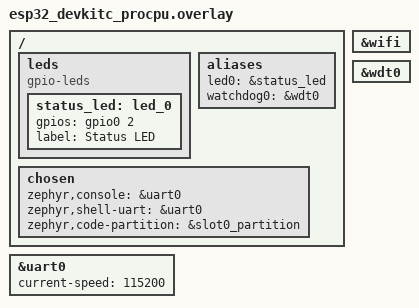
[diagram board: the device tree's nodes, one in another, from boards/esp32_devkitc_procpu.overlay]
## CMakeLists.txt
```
# SPDX-License-Identifier: Apache-2.0

cmake_minimum_required(VERSION 3.20.0)

find_package(Zephyr REQUIRED HINTS $ENV{ZEPHYR_BASE})
project(sample_with_mcuboot)

# Verify that this sample is built through sysbuild to ensure MCUboot is
# automatically included and that sample specific MCUboot configurations are
# used when building MCUboot.
test_sysbuild()

# Fügt Ihre C-Quelldateien zum "app"-Ziel hinzu.
target_sources(app PRIVATE
    src/main.c
    src/blinky.c
    src/wifi_mgmt.c
    src/ota_mgmt.c
    src/watchdog_mgmt.c
)

#set(DTC_OVERLAY_FILE ${CMAKE_CURRENT_SOURCE_DIR}/boards/${BOARD}.overlay)

target_include_directories(app PRIVATE 
    include
)
```

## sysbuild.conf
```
SB_CONFIG_BOOTLOADER_MCUBOOT=y
SB_CONFIG_BOOT_SIGNATURE_TYPE_ECDSA_P256=y
#SB_CONFIG_BOOT_SIGNATURE_TYPE_ED25519=y
SB_CONFIG_BOOT_SIGNATURE_KEY_FILE="C:/Users/SebastianR/Desktop/repos/zephyr-blinky-ota/zephyr-project/ecdsa.pem"

# necessary for some reason, as the mcuboot.conf is being overwritten or so
#SB_CONFIG_MCUBOOT_MODE_SWAP_SCRATCH=y
SB_CONFIG_MCUBOOT_MODE_SWAP_USING_MOVE=y
```

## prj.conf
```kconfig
# Empty file
# ======== Logging ========
CONFIG_LOG=y
#CONFIG_LOG_DEFAULT_LEVEL=3

# ======== Shell ========
CONFIG_SHELL=y
CONFIG_SHELL_BACKEND_SERIAL=y

# ======== Basic System and Hardware ========
CONFIG_GPIO=y
CONFIG_WATCHDOG=y
CONFIG_REBOOT=y
CONFIG_MAIN_STACK_SIZE=4096
CONFIG_SYSTEM_WORKQUEUE_STACK_SIZE=2048
CONFIG_HEAP_MEM_POOL_SIZE=65536

# ======== Networking =======
CONFIG_NETWORKING=y
CONFIG_NET_IPV4=y
CONFIG_NET_DHCPV4=y
CONFIG_NET_TCP=y
CONFIG_NET_SOCKETS=y
CONFIG_NET_MGMT=y
CONFIG_NET_MGMT_EVENT=y
CONFIG_NET_BUF_RX_COUNT=16
CONFIG_NET_BUF_TX_COUNT=16

# ======== WiFi ========
CONFIG_WIFI=y
CONFIG_WIFI_ESP32=y
CONFIG_NET_L2_WIFI_MGMT=y
CONFIG_HTTP_CLIENT=y

# ======== JSON Library ========
CONFIG_JSON_LIBRARY=y
# ======== MCUboot & OTA Support for the Application ========

CONFIG_IMG_MANAGER=y
CONFIG_MCUBOOT_IMG_MANAGER=y
CONFIG_IMG_BLOCK_BUF_SIZE=512
#CONFIG_MCUBOOT_SHELL=y # Erlaubt OTA-Befehle über die serielle Konsole
CONFIG_MCUBOOT_IMGTOOL_SIGN_VERSION="1.0.2+2"

#CONFIG_BOOT_IMAGE_ACCESS_HOOKS=y
# ======== Flash Configuration ========
CONFIG_FLASH=y
CONFIG_FLASH_MAP=y
CONFIG_STREAM_FLASH=y
CONFIG_FLASH_PAGE_LAYOUT=y

# ======== ESP32 Specific Flash Settings ========
CONFIG_ESPTOOLPY_FLASHMODE_QIO=y
CONFIG_ESPTOOLPY_FLASHFREQ_80M=y
CONFIG_ESPTOOLPY_FLASHSIZE_4MB=y

CONFIG_BOOTLOADER_MCUBOOT=y
CONFIG_IMG_BLOCK_BUF_SIZE=1024

CONFIG_GPIO_ESP32=y
CONFIG_PINCTRL=y

# For debugging GPIO issues
CONFIG_GPIO_SHELL=y
CONFIG_DEVICE_SHELL=y
```

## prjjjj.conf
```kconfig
# Empty file
# ======== Logging ========
CONFIG_LOG=y
#CONFIG_LOG_DEFAULT_LEVEL=3

# ======== Shell ========
CONFIG_SHELL=y
CONFIG_SHELL_BACKEND_SERIAL=y

# ======== Basic System and Hardware ========
CONFIG_GPIO=y
CONFIG_WATCHDOG=y
CONFIG_REBOOT=y
CONFIG_MAIN_STACK_SIZE=4096
CONFIG_SYSTEM_WORKQUEUE_STACK_SIZE=2048
CONFIG_HEAP_MEM_POOL_SIZE=65536

# ======== Networking =======
CONFIG_NETWORKING=y
CONFIG_NET_IPV4=y
CONFIG_NET_DHCPV4=y
CONFIG_NET_TCP=y
CONFIG_NET_SOCKETS=y
CONFIG_NET_MGMT=y
CONFIG_NET_MGMT_EVENT=y
CONFIG_NET_BUF_RX_COUNT=16
CONFIG_NET_BUF_TX_COUNT=16

# ======== WiFi ========
CONFIG_WIFI=y
CONFIG_WIFI_ESP32=y
CONFIG_NET_L2_WIFI_MGMT=y
CONFIG_HTTP_CLIENT=y

# ======== JSON Library ========
CONFIG_JSON_LIBRARY=y
# ======== MCUboot & OTA Support for the Application ========
#CONFIG_IMG_MANAGER=y
#CONFIG_MCUBOOT_IMG_MANAGER=y
#CONFIG_MCUBOOT_SHELL=y # Erlaubt OTA-Befehle über die serielle Konsole
CONFIG_MCUBOOT_IMGTOOL_SIGN_VERSION="1.0.2+2"

#CONFIG_BOOT_IMAGE_ACCESS_HOOKS=y
# ======== Flash Configuration ========
CONFIG_FLASH=y
CONFIG_FLASH_MAP=y
CONFIG_STREAM_FLASH=y
CONFIG_FLASH_PAGE_LAYOUT=y

# ======== ESP32 Specific Flash Settings ========
CONFIG_ESPTOOLPY_FLASHMODE_QIO=y
CONFIG_ESPTOOLPY_FLASHFREQ_80M=y
CONFIG_ESPTOOLPY_FLASHSIZE_4MB=y

CONFIG_BOOTLOADER_MCUBOOT=y
CONFIG_IMG_BLOCK_BUF_SIZE=1024

CONFIG_GPIO_ESP32=y
CONFIG_PINCTRL=y

# For debugging GPIO issues
CONFIG_GPIO_SHELL=y
CONFIG_DEVICE_SHELL=y
```

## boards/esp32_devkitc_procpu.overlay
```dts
/*
 * Application-specific hardware configuration and flash layout.
 * The flash partition map here MUST match the one in the .yml file.
 */

/ {
    /* Board-specific hardware customization for your application */
    leds {
        compatible = "gpio-leds";
        status_led: led_0 {
            gpios = <&gpio0 2 GPIO_ACTIVE_HIGH>;
            label = "Status LED";
        };
    };

    aliases {
        led0 = &status_led;
        watchdog0 = &wdt0;
    };

    chosen {
        zephyr,console = &uart0;
        zephyr,shell-uart = &uart0;
        zephyr,code-partition = &slot0_partition; /* Tells Zephyr where the app runs */
    };
};

&uart0 {
    status = "okay";
    current-speed = <115200>;
};

&wifi {
    status = "okay";
};

&wdt0 {
    status = "okay";
};
```

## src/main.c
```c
#include <zephyr/kernel.h>
#include <zephyr/logging/log.h>
#include <zephyr/dfu/mcuboot.h>

#include "app_config.h"
#include "blinky.h"
#include "wifi_mgmt.h"
#include "ota_mgmt.h"
#include "watchdog_mgmt.h"

LOG_MODULE_REGISTER(main, LOG_LEVEL_INF);

// Define a work item for the delayed confirmation
static void confirm_work_handler(struct k_work *work);
static K_WORK_DELAYABLE_DEFINE(confirm_work, confirm_work_handler);
static int main_task_handle;

static void confirm_work_handler(struct k_work *work)
{
    LOG_INF("Confirming running firmware as valid.");
    if (boot_write_img_confirmed() != 0) {
        LOG_ERR("Failed to confirm image! This may cause a revert on next boot.");
    } else {
        LOG_INF("Image confirmed successfully. The update is now permanent.");
        ota_check_for_update();
    }
}

/* OTA status callback */
static void ota_status_changed(ota_status_t status)
{
    switch (status) {
    case OTA_STATUS_CHECKING:
        LOG_INF("OTA: Checking for updates...");
        break;
    case OTA_STATUS_UPDATE_AVAILABLE:
        LOG_INF("OTA: Update available, preparing download");
        break;
    case OTA_STATUS_DOWNLOADING:
        LOG_INF("OTA: Downloading firmware update");
        break;
    case OTA_STATUS_DOWNLOAD_COMPLETE:
        LOG_INF("OTA: Download complete, preparing to apply");
        break;
    case OTA_STATUS_APPLYING:
        LOG_INF("OTA: Applying update, device will reboot");
        break;
    case OTA_STATUS_ERROR:
        LOG_ERR("OTA: Error occurred, code: %d", ota_get_last_error());
        break;
    default:
        break;
    }
}

int main(void)
{    
    LOG_INF("====================================");
    LOG_INF("   ESP32 OTA Application Booting    ");
    LOG_INF("====================================");

    // This is the most important part after an OTA update.
    // Check if we are running an unconfirmed image.
    if (boot_is_img_confirmed() == 0) {
        LOG_WRN("Running new firmware in TEST mode.");
        LOG_WRN("Scheduling confirmation in 30 seconds.");
        // We wait 30 seconds to ensure the system is stable (e.g., WiFi connects)
        // before making the update permanent.
        k_work_schedule(&confirm_work, K_SECONDS(30));
    } else {
        LOG_INF("Running a confirmed image.");
    }

    ota_register_status_callback(ota_status_changed);
    char current_ver[16];
    int rc = ota_get_running_firmware_version(current_ver, sizeof(current_ver));
    if (rc == 0) {
        LOG_INF("Current running version: %s", current_ver);
    } else {
        LOG_WRN("Somethings wrong with the version getter");
    }
    bool ip_printed = false;

    watchdog_manager_init(K_SECONDS(30));
    LOG_INF("Watchdog initialized!");
    main_task_handle = watchdog_manager_register_task();

    LOG_INF("Main loop started. System is running.");
    while (1) {
        k_sleep(K_SECONDS(5));
        watchdog_manager_check_in(main_task_handle);

        if(!ip_printed) {
            char ip_str[16];
            int result = wifi_get_ip_address_public(ip_str, sizeof(ip_str));
            if (result == 0) {
                LOG_INF("IP: %s", ip_str);
                ip_printed = true;
            } else {
                LOG_INF("No IP");
            }
        }
    }
    
    return 0;
}
```

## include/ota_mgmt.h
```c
#ifndef OTA_MGMT_H
#define OTA_MGMT_H

#include <zephyr/kernel.h>
#include <stdint.h>
#include <stdbool.h>
#include <zephyr/dfu/mcuboot.h>

#ifdef __cplusplus
extern "C" {
#endif

/* OTA update status codes */
typedef enum {
    OTA_STATUS_IDLE = 0,
    OTA_STATUS_CHECKING,
    OTA_STATUS_UPDATE_AVAILABLE,
    OTA_STATUS_DOWNLOADING,
    OTA_STATUS_DOWNLOAD_COMPLETE,
    OTA_STATUS_APPLYING,
    OTA_STATUS_ERROR,
} ota_status_t;

/* OTA error codes */
typedef enum {
    OTA_ERR_NONE = 0,
    OTA_ERR_SERVER_CONNECT,
    OTA_ERR_DOWNLOAD_FAILED,
    OTA_ERR_FLASH_INIT,
    OTA_ERR_FLASH_WRITE,
    OTA_ERR_VERIFICATION,
    OTA_ERR_APPLY_UPDATE,
    OTA_ERR_INVALID_IMAGE,
} ota_error_t;

/**
 * @brief Initialize OTA management subsystem
 * 
 * This function is called automatically during system initialization.
 * 
 * @return 0 on success, negative error code on failure
 */
int ota_mgmt_init(void);

/**
 * @brief Manually trigger an OTA update check
 * 
 * @return 0 if check was started, negative error code on failure
 */
int ota_check_for_update(void);

/**
 * @brief Get current OTA status
 * 
 * @return Current OTA status code
 */
ota_status_t ota_get_status(void);

/**
 * @brief Get last OTA error
 * 
 * @return Last error code
 */
ota_error_t ota_get_last_error(void);

/**
 * @brief Register callback for OTA status changes
 * 
 * @param callback Function to call when OTA status changes
 */
void ota_register_status_callback(void (*callback)(ota_status_t status));

/**
 * @brief Get the version of the currently running firmware.
 *
 * This function reads the image header from the primary (active) slot,
 * formats the semantic version into a string, and stores it in the
 * provided buffer.
 *
 * @param buf       A character buffer to store the version string.
 * @param buf_size  The size of the provided buffer.
 *
 * @return 0 on success.
 * @return -EIO if the image header could not be read.
 * @return -ENOMEM if the provided buffer is too small to hold the version string.
 * @return A negative error code from the underlying boot/flash functions on other failures.
 */
int ota_get_running_firmware_version(char *buf, size_t buf_size);

static void ota_enter_backoff_state(void);

#ifdef __cplusplus
}
#endif

#endif /* OTA_MGMT_H */
```

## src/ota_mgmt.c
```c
#include <zephyr/kernel.h>
#include <zephyr/net/socket.h>
#include <zephyr/storage/flash_map.h>
#include <zephyr/dfu/mcuboot.h>
#include <zephyr/storage/stream_flash.h>
#include <zephyr/sys/reboot.h>
#include <zephyr/logging/log.h>
#include <zephyr/init.h>
#include <zephyr/net/http/client.h>
#include <zephyr/net/net_ip.h>
#include <zephyr/data/json.h>
#include <string.h>
#include "wifi_mgmt.h"
#include "app_config.h"
#include "ota_mgmt.h"
#include "blinky.h"
#include <zephyr/devicetree.h>
#include <zephyr/dfu/flash_img.h>
#include <stdio.h>
#include "watchdog_mgmt.h"


LOG_MODULE_REGISTER(ota_mgmt, LOG_LEVEL_INF);

struct flash_img_context image_ctx;

/* OTA state variables */
static struct k_work_delayable ota_check_work;
static ota_status_t current_status = OTA_STATUS_IDLE;
static ota_error_t last_error = OTA_ERR_NONE;
static void (*status_callback)(ota_status_t) = NULL;

/* HTTP client context */
static struct http_request http_req;
static uint8_t http_recv_buf[1024];
static int64_t content_length = 0;
static size_t total_downloaded = 0;
static bool headers_complete = false;
static int retry_count = 0;
static int http_sock = -1;

/* Watchdog */
static int ota_task_handle = -1;

/* Version parsing from JSON */
struct version_info {
    const char *version;
    int size;
};

static struct json_obj_descr version_descr[] = {
    JSON_OBJ_DESCR_PRIM(struct version_info, version, JSON_TOK_STRING),
    JSON_OBJ_DESCR_PRIM(struct version_info, size, JSON_TOK_NUMBER),
};

/* Forward declarations */
static void ota_check_work_handler(struct k_work *work);
static int perform_update(void);
static void update_status(ota_status_t new_status);
static int apply_update(void);
static int create_http_socket(const char *host, int port);
static void ota_enter_backoff_state(void);


/* Update OTA status and trigger callback if registered */
static void update_status(ota_status_t new_status)
{
    if (current_status != new_status) {
        current_status = new_status;
        
        /* Update LED pattern based on status */
        switch (new_status) {
        case OTA_STATUS_DOWNLOADING:
            blinky_set_interval(LED_SLOW_BLINK_MS);
            break;
        case OTA_STATUS_APPLYING:
            blinky_set_interval(LED_FAST_BLINK_MS);
            break;
        case OTA_STATUS_ERROR:
            blinky_set_interval(LED_ERROR_PATTERN);
            break;
        default:
            blinky_set_interval(LED_BLINK_INTERVAL_MS);
            break;
        }
        
        if (status_callback != NULL) {
            status_callback(new_status);
        }
    }
}

/* Set error and update status */
static void set_error(ota_error_t error)
{
    last_error = error;
    update_status(OTA_STATUS_ERROR);
}

/* Direkte Boot-Trailer Manipulation */
static int manual_boot_request_upgrade(void)
{
    const struct flash_area *fa;
    int ret;
    
    ret = flash_area_open(DT_FIXED_PARTITION_ID(DT_NODELABEL(slot1_partition)), &fa);
    if (ret) {
        LOG_ERR("Cannot open slot1: %d", ret);
        return ret;
    }
    
    /* Boot-Trailer am Ende von Slot1 schreiben */
    struct {
        uint8_t image_ok;
        uint8_t copy_done;
        uint8_t reserved[14];
        uint32_t magic;
    } __packed trailer = {
        .image_ok = 0x01,     // BOOT_FLAG_SET
        .copy_done = 0xFF,    // BOOT_FLAG_UNSET
        .magic = 0x96f3b83c   // BOOT_MAGIC
    };
    
    size_t trailer_offset = fa->fa_size - sizeof(trailer);
    
    ret = flash_area_write(fa, trailer_offset, &trailer, sizeof(trailer));
    if (ret) {
        LOG_ERR("Failed to write boot trailer: %d", ret);
        flash_area_close(fa);
        return ret;
    }
    
    LOG_INF("✓ Boot trailer written manually");
    flash_area_close(fa);
    return 0;
}

void debug_image_headers(void)
{
    LOG_INF("=== Image Header Debug ===");
    
    struct mcuboot_img_header header;
    int ret;
    
    /* Slot0 (aktuell laufend) prüfen */
    ret = boot_read_bank_header(DT_FIXED_PARTITION_ID(DT_NODELABEL(slot0_partition)), &header, sizeof(header));
    if (ret == 0) {
        LOG_INF("Slot0 - Image size: %u", header.h.v1.image_size);
        LOG_INF("Slot0 - Version: %u.%u.%u+%u", 
               header.h.v1.sem_ver.major,
               header.h.v1.sem_ver.minor,
               header.h.v1.sem_ver.revision,
               header.h.v1.sem_ver.build_num);
    } else {
        LOG_ERR("Failed to read slot0 header: %d", ret);
    }
    
    /* Slot1 (OTA Update) prüfen */
    ret = boot_read_bank_header(DT_FIXED_PARTITION_ID(DT_NODELABEL(slot1_partition)), &header, sizeof(header));
    if (ret == 0) {
        LOG_INF("✓ Slot1 - Valid image found!");
        LOG_INF("Slot1 - Image size: %u", header.h.v1.image_size);
        LOG_INF("Slot1 - Version: %u.%u.%u+%u", 
               header.h.v1.sem_ver.major,
               header.h.v1.sem_ver.minor,
               header.h.v1.sem_ver.revision,
               header.h.v1.sem_ver.build_num);
    } else {
        LOG_ERR("✗ Slot1 - No valid image found: %d", ret);
        
        /* Raw Flash-Daten zur Diagnose lesen */
        const struct flash_area *fa;
        if (flash_area_open(DT_FIXED_PARTITION_ID(DT_NODELABEL(slot1_partition)), &fa) == 0) {
            uint32_t magic;
            flash_area_read(fa, 0, &magic, sizeof(magic));
            LOG_ERR("Slot1 raw magic: 0x%08x (expected: 0x96f3b83d)", magic);
            flash_area_close(fa);
        }
    }
}

int ota_get_running_firmware_version(char *buf, size_t buf_size)
{
    struct mcuboot_img_header header;
    int rc;

    /*
     * Use boot_fetch_active_slot() to reliably get the ID of the slot
     * from which the current application was booted. This is more robust
     * than hardcoding the slot0 ID, especially in revert scenarios.
     */
    uint8_t active_slot_id = boot_fetch_active_slot();

    rc = boot_read_bank_header(active_slot_id, &header, sizeof(header));
    if (rc != 0) {
        LOG_ERR("Failed to read running image header from slot %u. Error: %d",
                active_slot_id, rc);
        return rc; // Propagate the error (-EIO is common for empty/bad slots)
    }

    /* Format the version string into the provided buffer */
    rc = snprintf(buf, buf_size, "%u.%u.%u",
                  header.h.v1.sem_ver.major,
                  header.h.v1.sem_ver.minor,
                  header.h.v1.sem_ver.revision);

    /*
     * snprintf returns the number of characters that *would have been* written.
     * We must check if this number is greater than or equal to the buffer size,
     * which indicates truncation.
     */
    if (rc < 0 || rc >= buf_size) {
        LOG_ERR("Buffer too small for version string. Required: %d, available: %zu",
                rc, buf_size);
        return -ENOMEM; // No memory/space available
    }

    return 0; // Success
}

/* Create HTTP socket connection */
static int create_http_socket(const char *host, int port)
{
    struct zsock_addrinfo hints, *result;
    //struct sockaddr_in addr;
    int sock;
    int ret;
    
    sock = zsock_socket(AF_INET, SOCK_STREAM, IPPROTO_TCP);
    if (sock < 0) {
        LOG_ERR("Failed to create socket: %d", errno);
        return -1;
    }
    
    /* Set socket timeout */
    struct zsock_timeval timeout = {
        .tv_sec = 30,
        .tv_usec = 0,
    };
    
    zsock_setsockopt(sock, SOL_SOCKET, SO_RCVTIMEO, &timeout, sizeof(timeout));
    zsock_setsockopt(sock, SOL_SOCKET, SO_SNDTIMEO, &timeout, sizeof(timeout));
    
    /* Setup address resolution */
    memset(&hints, 0, sizeof(hints));
    hints.ai_family = AF_INET;
    hints.ai_socktype = SOCK_STREAM;
    
    char port_str[8];
    snprintf(port_str, sizeof(port_str), "%d", port);
    
    ret = zsock_getaddrinfo(host, port_str, &hints, &result);
    if (ret != 0) {
        LOG_ERR("Failed to resolve hostname %s: %d", host, ret);
        zsock_close(sock);
        return -1;
    }
    
    /* Connect */
    ret = zsock_connect(sock, result->ai_addr, result->ai_addrlen);
    zsock_freeaddrinfo(result);
    
    if (ret < 0) {
        LOG_ERR("Failed to connect to %s:%d: %d", host, port, errno);
        zsock_close(sock);
        return -1;
    }
    
    LOG_INF("Connected to %s:%d", host, port);
    return sock;
}

/* HTTP response callback */
static int http_response_cb(struct http_response *rsp, enum http_final_call final_data, void *user_data)
{
    int ret = 0;
    
    /* Feed watchdog to prevent reset during download */
    watchdog_manager_check_in(ota_task_handle);

    /* Check if this is the first time we get body data */
    if (!headers_complete && rsp->body_frag_len > 0) {
        if (rsp->http_status_code != 200) {
            LOG_ERR("HTTP request failed with status: %d %s", rsp->http_status_code, rsp->http_status);
            set_error(OTA_ERR_DOWNLOAD_FAILED);
            return -1;
        }
        headers_complete = true;
        content_length = rsp->content_length;
        LOG_INF("HTTP headers complete, content length: %lld", content_length);
        
        /* If checking version, parse the JSON response */
        if (current_status == OTA_STATUS_CHECKING) {
            struct version_info version = {0};
            
            ret = json_obj_parse(rsp->body_frag_start, rsp->body_frag_len,
                               version_descr, ARRAY_SIZE(version_descr),
                               &version);
            
            if (ret > 0 && version.version) {
                LOG_INF("Server version: %s", version.version);
                
                /* Compare with current version */
                char current_ver[16];
                int rc = ota_get_running_firmware_version(current_ver, sizeof(current_ver));
                if (strcmp(version.version, current_ver) != 0) {
                    LOG_INF("New version available: %s (current: %s)",
                           version.version, current_ver);
                    update_status(OTA_STATUS_UPDATE_AVAILABLE);
                    
                    /* Start download after a short delay */
                    k_work_schedule(&ota_check_work, K_SECONDS(5));
                } else {
                    LOG_INF("Already running latest version");
                    update_status(OTA_STATUS_IDLE);
                }
            } else {
                LOG_ERR("Failed to parse version info");
                set_error(OTA_ERR_SERVER_CONNECT);
            }
            
            return 0;
        }

        if (current_status == OTA_STATUS_DOWNLOADING) {
            LOG_INF("Flash initialized for firmware download");
            total_downloaded = 0;
        }
    }
    
    /* Process body data for firmware download */
    if (headers_complete && current_status == OTA_STATUS_DOWNLOADING && 
        rsp->body_frag_len > 0) {
        
        ret = flash_img_buffered_write(&image_ctx, 
                rsp->body_frag_start,
                rsp->body_frag_len, 
                (final_data == HTTP_DATA_FINAL));

        if (ret < 0) {
            LOG_ERR("Flash write error: %d", ret);
            set_error(OTA_ERR_FLASH_WRITE);
            return ret;
        }
        
        total_downloaded += rsp->body_frag_len;
        
        if (total_downloaded % 4096 == 0 || final_data == HTTP_DATA_FINAL) {
            double progress = (double)total_downloaded * 100.0 / content_length;
            LOG_INF("Downloaded: %zu bytes (%.1f%%)", total_downloaded, progress);
        }
        
        /* Check if download is complete */
        if (final_data == HTTP_DATA_FINAL) {
            LOG_INF("Firmware download complete: %zu bytes", total_downloaded);
        }
    }
    
    return 0;
}

/* Check for firmware updates */
static int check_for_update(void)
{
    if (!wifi_is_connected()) {
        LOG_WRN("WiFi not connected (yet), skipping update check");
        return -ENOTCONN;
    }
    
    update_status(OTA_STATUS_CHECKING);
    
    /* try to create socket connection */
    http_sock = create_http_socket(OTA_SERVER_HOST, OTA_SERVER_PORT);
    if (http_sock < 0) {
        LOG_ERR("Server connection failed. Entering 1-hour backoff.");
        ota_enter_backoff_state();
        return http_sock;
    }
    
    /* Setup HTTP request for version check */
    memset(&http_req, 0, sizeof(http_req));
    
    http_req.method = HTTP_GET;
    http_req.url = OTA_VERSION_URL;
    http_req.host = OTA_SERVER_HOST;
    http_req.protocol = "HTTP/1.1";
    http_req.response = http_response_cb;
    http_req.recv_buf = http_recv_buf;
    http_req.recv_buf_len = sizeof(http_recv_buf);
    
    headers_complete = false;
    
    LOG_INF("Checking for updates at http://%s:%d%s", OTA_SERVER_HOST, OTA_SERVER_PORT, OTA_VERSION_URL);
    int ret = http_client_req(http_sock, &http_req, 5000, NULL); //blocks until done
    
    /* Close socket */
    zsock_close(http_sock);
    http_sock = -1;
    
    /* in case something went wrong */
    if (ret < 0) {
        LOG_ERR("Server connection failed. Entering 1-hour backoff.");
        ota_enter_backoff_state();
    }
    
    return ret;
}

/* Download and install firmware update */
static int perform_update(void)
{
    LOG_INF("Tryning to download firmware");

    if (!wifi_is_connected()) {
        LOG_WRN("WiFi not connected, cannot download update");
        ota_enter_backoff_state();
        return -ENOTCONN;
    }
    
    update_status(OTA_STATUS_DOWNLOADING);
    
    //int ret = flash_img_init(&image_ctx);
    int ret = flash_img_init_id(&image_ctx, DT_FIXED_PARTITION_ID(DT_NODELABEL(slot1_partition)));
    LOG_INF("area ID of slot1: %d", DT_FIXED_PARTITION_ID(DT_NODELABEL(slot1_partition)));

    if (ret != 0) {
        LOG_ERR("Failed to initialize flash context: %d", ret);
        set_error(OTA_ERR_FLASH_INIT);
        ota_enter_backoff_state();
        return ret;
    }

    uint8_t area_id = flash_img_get_upload_slot();
    LOG_INF("Flash image using area ID: %d", area_id);

    /* Create socket connection */
    http_sock = create_http_socket(OTA_SERVER_HOST, OTA_SERVER_PORT);
    if (http_sock < 0) {
        set_error(OTA_ERR_SERVER_CONNECT);
        LOG_ERR("Server connection failed. Entering 1-hour backoff.");
        ota_enter_backoff_state();
        return -ECONNREFUSED;
    }
    /* Setup HTTP request for firmware download */
    memset(&http_req, 0, sizeof(http_req));

    http_req.method = HTTP_GET;
    http_req.url = OTA_FIRMWARE_URL;
    http_req.host = OTA_SERVER_HOST;
    http_req.protocol = "HTTP/1.1";
    http_req.response = http_response_cb;
    http_req.recv_buf = http_recv_buf;
    http_req.recv_buf_len = sizeof(http_recv_buf);
    
    headers_complete = false;
    total_downloaded = 0; 

    LOG_INF("Downloading firmware from http://%s:%d%s", OTA_SERVER_HOST, OTA_SERVER_PORT, OTA_FIRMWARE_URL);

    ret = http_client_req(http_sock, &http_req, OTA_DOWNLOAD_TIMEOUT_MS, NULL); // blocks until done

    /* Close socket */
    zsock_close(http_sock);
    http_sock = -1;
    
    if (ret < 0) {
        LOG_ERR("Failed to download firmware: %d", ret);
        set_error(OTA_ERR_DOWNLOAD_FAILED);
        
        /* Retry logic */
        if (++retry_count < OTA_MAX_DOWNLOAD_RETRIES) {
            LOG_INF("Retrying download (%d/%d) in 5 seconds...", 
                   retry_count + 1, OTA_MAX_DOWNLOAD_RETRIES);
            k_work_schedule(&ota_check_work, K_SECONDS(5));
        } else {
            LOG_ERR("Max retry attempts reached, giving up");
            retry_count = 0;
            update_status(OTA_STATUS_IDLE);
            ota_enter_backoff_state();
        }
    } else {
        LOG_INF("Firmware download successful.");
        update_status(OTA_STATUS_DOWNLOAD_COMPLETE);

        // The download is fully complete, and the HTTP client is closed.
        // The image_ctx is no longer in active use. NOW it is safe
        // to schedule the final "apply" step.
        k_work_schedule(&ota_check_work, K_MSEC(100)); // A short delay is fine.
        /* Reset retry counter on success */
        retry_count = 0;
    }
    
    return ret;
}

/* Apply downloaded update */
static int apply_update(void)
{
    update_status(OTA_STATUS_APPLYING);
    
    LOG_INF("=== Boot Status Debug ===");
    int swap_type = mcuboot_swap_type();
    LOG_INF("Current swap type: %d", swap_type);

    const struct flash_area *fa;
    uint32_t magic;
    int ret_dbg;
    
    
    /* Slot1 direkt aus Flash lesen */
    ret_dbg = flash_area_open(DT_FIXED_PARTITION_ID(DT_NODELABEL(slot1_partition)), &fa);
    if (ret_dbg != 0) {
        LOG_ERR("Cannot open slot1: %d", ret_dbg);
        return ret_dbg;
    }
    
    /* Erste 4 Bytes lesen (das ist der Magic-Wert) */
    ret_dbg = flash_area_read(fa, 0, &magic, sizeof(magic));
    if (ret_dbg == 0) {
        LOG_INF("Slot1 - First 4 bytes (magic): 0x%08x", magic);
    }

    debug_image_headers();

    /* Mark image for testing */
    int ret = boot_request_upgrade(BOOT_UPGRADE_TEST);
    //int ret = manual_boot_request_upgrade();
    if (ret != 0) {
        LOG_ERR("Failed to request upgrade: %d", ret);
        set_error(OTA_ERR_APPLY_UPDATE);
        return ret;
    }
    
    LOG_INF("Update ready - rebooting in 3 seconds");
    watchdog_manager_check_in(ota_task_handle);
    k_sleep(K_SECONDS(3));
    sys_reboot(SYS_REBOOT_WARM); //SYS_REBOOT_COLD
    
    return 0; /* Will never reach here */
}

/* OTA check work handler */
static void ota_check_work_handler(struct k_work *work)
{
    ARG_UNUSED(work);
    
    if (!watchdog_manager_is_monitoring_enabled(ota_task_handle)) {
        LOG_INF("OTA is in backoff state. Will try again later.");
        watchdog_manager_enable_monitoring(ota_task_handle, true);
        update_status(OTA_STATUS_IDLE);
        return;
    }

    watchdog_manager_check_in(ota_task_handle);
    
    switch (current_status) {
        case OTA_STATUS_IDLE:
            check_for_update();
            break;
            
        case OTA_STATUS_UPDATE_AVAILABLE:
            perform_update();
            break;
            
        case OTA_STATUS_DOWNLOAD_COMPLETE:
            apply_update();
            break;
            
        default:
            break;
    }
}

static void ota_enter_backoff_state(void) {
    watchdog_manager_enable_monitoring(ota_task_handle, false);
    k_work_schedule(&ota_check_work, K_HOURS(1));
    set_error(OTA_ERR_SERVER_CONNECT);
}

/* Public functions */
int ota_check_for_update(void)
{
    if (current_status != OTA_STATUS_IDLE) {
        LOG_WRN("OTA operation already in progress");
        return -EBUSY;
    }
    
    return check_for_update();
}

ota_status_t ota_get_status(void)
{
    return current_status;
}

ota_error_t ota_get_last_error(void)
{
    return last_error;
}

void ota_register_status_callback(void (*callback)(ota_status_t status))
{
    status_callback = callback;
}

int ota_mgmt_init(void)
{
    ota_task_handle = watchdog_manager_register_task();

    k_work_init_delayable(&ota_check_work, ota_check_work_handler);

    if (boot_is_img_confirmed()) {
        LOG_INF("Scheduling initial OTA check in 30 seconds.");
        k_work_schedule(&ota_check_work, K_SECONDS(30));
    }

    LOG_INF("OTA management subsystem initialized");
    return 0;
}

/* Auto-initialize at APPLICATION level */
SYS_INIT(ota_mgmt_init, APPLICATION, CONFIG_APPLICATION_INIT_PRIORITY);
```

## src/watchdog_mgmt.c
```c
#include "watchdog_mgmt.h"
#include <zephyr/drivers/watchdog.h>
#include <zephyr/logging/log.h>
#include <stdatomic.h>

LOG_MODULE_REGISTER(wdt_mgr, LOG_LEVEL_INF);

#define MAX_MONITORED_TASKS 4 // Maximale Anzahl an Tasks, die überwacht werden können

static const struct device *wdt_dev;
static int wdt_channel_id;

static atomic_uint g_task_check_ins[MAX_MONITORED_TASKS];
static atomic_bool g_task_monitoring_enabled[MAX_MONITORED_TASKS];
static atomic_int g_registered_tasks_count = ATOMIC_VAR_INIT(0);

static struct k_timer wdt_mgr_timer;

/*
 * This is the core logic. It's a timer callback that runs periodically.
 */
static void watchdog_manager_check_tasks(struct k_timer *timer)
{
    bool all_active_tasks_ok = true;
    int task_count = atomic_load(&g_registered_tasks_count);

    for (int i = 0; i < task_count; i++) {
        // ONLY check tasks that are supposed to be active.
        if (atomic_load(&g_task_monitoring_enabled[i])) {
            if (atomic_exchange(&g_task_check_ins[i], 0) == 0) {
                LOG_ERR("Watchdog: Monitored task %d failed to check in!", i);
                all_active_tasks_ok = false;
            }
        }
    }

    if (all_active_tasks_ok) {
        if (wdt_dev) {
            wdt_feed(wdt_dev, wdt_channel_id);
            LOG_DBG("All %d tasks checked in. Watchdog fed.", task_count);
        }
    } else {
        LOG_WRN("Watchdog not fed due to missing check-in. System will reset soon.");
        // We do nothing, letting the hardware watchdog time out.
    }
}

int watchdog_manager_init(k_timeout_t check_interval)
{
    wdt_dev = DEVICE_DT_GET(DT_ALIAS(watchdog0));
    if (!device_is_ready(wdt_dev)) {
        LOG_ERR("Hardware watchdog device not found or not ready.");
        return -ENODEV;
    }

    struct wdt_timeout_cfg wdt_config = {
        .window.min = 0,
        .window.max = 60000, // 60-Sekunden-Hardware-Timeout
        .callback = NULL,
        .flags = WDT_FLAG_RESET_SOC,
    };
    wdt_channel_id = wdt_install_timeout(wdt_dev, &wdt_config);
    if (wdt_channel_id < 0) {
        LOG_ERR("Failed to install watchdog timeout: %d", wdt_channel_id);
        return wdt_channel_id;
    }
    wdt_setup(wdt_dev, WDT_OPT_PAUSE_HALTED_BY_DBG);

    // Initialisiere und starte unseren periodischen Software-Check-Timer
    k_timer_init(&wdt_mgr_timer, watchdog_manager_check_tasks, NULL);
    k_timer_start(&wdt_mgr_timer, check_interval, check_interval);

    LOG_INF("Watchdog Manager initialized. Check interval: %llu ms, HW timeout: %u ms",
            check_interval.ticks, wdt_config.window.max);

    return 0;
}

int watchdog_manager_register_task(void)
{
    int handle = atomic_fetch_add(&g_registered_tasks_count, 1);
    if (handle >= MAX_MONITORED_TASKS) {
        atomic_store(&g_registered_tasks_count, MAX_MONITORED_TASKS); // Korrigiere den Zähler
        LOG_ERR("Cannot register more tasks. Limit of %d reached.", MAX_MONITORED_TASKS);
        return -ENOMEM;
    }

    // Initialisiere das Check-in-Flag auf 0. Der Task muss sofort einchecken.
    atomic_store(&g_task_monitoring_enabled[handle], true);
    atomic_store(&g_task_check_ins[handle], 0);
    LOG_INF("Task registered with handle %d", handle);
    return handle;
}

void watchdog_manager_check_in(int task_handle)
{
    if (task_handle < 0 || task_handle >= MAX_MONITORED_TASKS) {
        return; // Ungültiges Handle
    }
    atomic_store(&g_task_check_ins[task_handle], 1);
}

void watchdog_manager_enable_monitoring(int task_handle, bool enable)
{
    if (task_handle < 0 || task_handle >= MAX_MONITORED_TASKS) {
        return;
    }
    atomic_store(&g_task_monitoring_enabled[task_handle], enable);
    if (enable) {
        // When re-enabling, reset the check-in flag to force an immediate check-in.
        atomic_store(&g_task_check_ins[task_handle], 0);
    }
}

bool watchdog_manager_is_monitoring_enabled(int task_handle)
{
    if (task_handle < 0 || task_handle >= MAX_MONITORED_TASKS) {
        return false;
    }
    return atomic_load(&g_task_monitoring_enabled[task_handle]);
}
```
